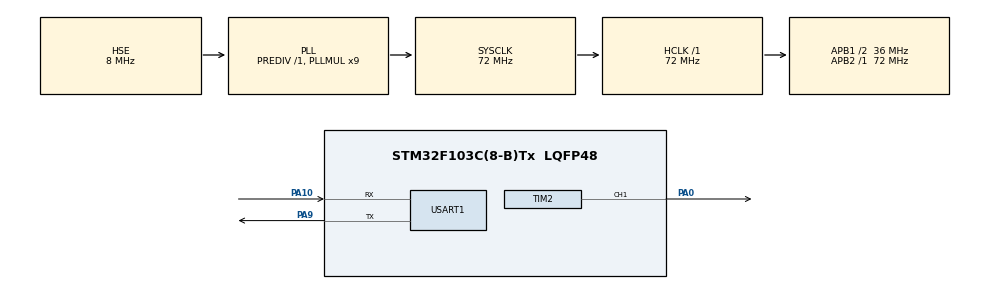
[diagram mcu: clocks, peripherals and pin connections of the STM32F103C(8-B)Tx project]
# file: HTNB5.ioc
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Mcu.Family=STM32F1
Mcu.Name=STM32F103C(8-B)Tx
Mcu.Package=LQFP48
NVIC.PriorityGroup=NVIC_PRIORITYGROUP_4
NVIC.USART1_IRQn=true\:2\:0\:true\:false\:true\:true\:true\:true
PA0-WKUP.Signal=S_TIM2_CH1_ETR
PA10.Mode=Asynchronous
PA10.Signal=USART1_RX
PA9.Mode=Asynchronous
PA9.Signal=USART1_TX
PD0-OSC_IN.Mode=HSE-External-Oscillator
PD0-OSC_IN.Signal=RCC_OSC_IN
PD1-OSC_OUT.Mode=HSE-External-Oscillator
PD1-OSC_OUT.Signal=RCC_OSC_OUT
ProjectManager.HeapSize=0x200
ProjectManager.StackSize=0x400
ProjectManager.TargetToolchain=Makefile
RCC.AHBFreq_Value=72000000
RCC.APB1CLKDivider=RCC_HCLK_DIV2
RCC.APB1Freq_Value=36000000
RCC.APB1TimFreq_Value=72000000
RCC.APB2Freq_Value=72000000
RCC.APB2TimFreq_Value=72000000
RCC.HCLKFreq_Value=72000000
RCC.PLLMUL=RCC_PLL_MUL9
RCC.PLLSourceVirtual=RCC_PLLSOURCE_HSE
RCC.SYSCLKFreq_VALUE=72000000
RCC.SYSCLKSource=RCC_SYSCLKSOURCE_PLLCLK
RCC.USBFreq_Value=72000000
SH.S_TIM2_CH1_ETR.0=TIM2_CH1,PWM Generation1 CH1
TIM2.Channel-PWM\ Generation1\ CH1=TIM_CHANNEL_1
TIM2.Period=999
TIM2.Prescaler=71
USART1.VirtualMode=VM_ASYNC
VP_SYS_VS_ND.Mode=No_Debug
board=custom

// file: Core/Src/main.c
/* USER CODE BEGIN Header */
/**
  ******************************************************************************
  * @file           : main.c
  * @brief          : Main program body
  ******************************************************************************
  * @attention
  *
  * Copyright (c) 2026 STMicroelectronics.
  * All rights reserved.
  *
  * This software is licensed under terms that can be found in the LICENSE file
  * in the root directory of this software component.
  * If no LICENSE file comes with this software, it is provided AS-IS.
  *
  ******************************************************************************
  */
/* USER CODE END Header */

#include "main.h"

/* USER CODE BEGIN Includes */
#include <string.h>
#include <stdio.h>
#include <stdlib.h>
/* USER CODE END Includes */

/* USER CODE BEGIN PD */
#define RX_BUFFER_SIZE 100
/* USER CODE END PD */

TIM_HandleTypeDef htim2;

UART_HandleTypeDef huart1;

/* USER CODE BEGIN PV */

uint8_t rx_data;

char rx_buffer[RX_BUFFER_SIZE];
uint8_t rx_index = 0;

volatile uint8_t command_ready = 0;

/* Trạng thái LED */
uint8_t led_on = 0;

/* Mức PWM gần nhất, mặc định 50% */
uint8_t pwm_percent = 50;

char tx_buffer[100];

/* USER CODE END PV */

void SystemClock_Config(void);
static void MX_GPIO_Init(void);
static void MX_TIM2_Init(void);
static void MX_USART1_UART_Init(void);

/* USER CODE BEGIN PFP */

void Set_PWM(uint8_t percent);
void Process_Command(void);
void UART_Send_String(char *str);

/* USER CODE END PFP */

/* USER CODE BEGIN 0 */

/* Hàm đặt duty PWM từ 0 -> 100% */
void Set_PWM(uint8_t percent)
{
    uint32_t compare;

    if(percent > 100)
    {
        percent = 100;
    }

    /*
     * ARR = 999
     * => tổng 1000 count
     *
     * 10%  = 100
     * 50%  = 500
     * 100% = 1000
     */
    compare = percent * 10;

    __HAL_TIM_SET_COMPARE(&htim2,
                          TIM_CHANNEL_1,
                          compare);
}

/* Gửi chuỗi qua UART */
void UART_Send_String(char *str)
{
    HAL_UART_Transmit(&huart1,
                      (uint8_t *)str,
                      strlen(str),
                      1000);
}

/* Xử lý lệnh nhận được */
void Process_Command(void)
{
    /* ---------- ON ---------- */
    if(strcmp(rx_buffer, "ON") == 0)
    {
        led_on = 1;

        /* Khôi phục mức PWM gần nhất */
        Set_PWM(pwm_percent);

        UART_Send_String("LED ON\r\n");
    }

    /* ---------- OFF ---------- */
    else if(strcmp(rx_buffer, "OFF") == 0)
    {
        led_on = 0;

        /* Tắt LED thực tế */
        Set_PWM(0);

        UART_Send_String("LED OFF\r\n");
    }

    /* ---------- PWM:xx ---------- */
    else if(strncmp(rx_buffer, "PWM:", 4) == 0)
    {
        int value;

        value = atoi(&rx_buffer[4]);

        if(value >= 0 && value <= 100)
        {
            /*
             * Luôn cập nhật giá trị PWM đã cấu hình,
             * kể cả khi LED đang OFF.
             */
            pwm_percent = (uint8_t)value;

            /*
             * Chỉ thay đổi độ sáng thực tế
             * nếu LED đang ON.
             */
            if(led_on)
            {
                Set_PWM(pwm_percent);
            }

            sprintf(tx_buffer,
                    "PWM = %d%%\r\n",
                    pwm_percent);

            UART_Send_String(tx_buffer);
        }
        else
        {
            UART_Send_String("PWM invalid\r\n");
        }
    }

    /* ---------- Status ---------- */
    else if(strcmp(rx_buffer, "Status") == 0)
    {
        if(led_on)
        {
            sprintf(tx_buffer,
                    "LED: ON, PWM: %d%%\r\n",
                    pwm_percent);
        }
        else
        {
            sprintf(tx_buffer,
                    "LED: OFF, PWM: %d%%\r\n",
                    pwm_percent);
        }

        UART_Send_String(tx_buffer);
    }

    /* ---------- Sai lệnh ---------- */
    else
    {
        UART_Send_String("Unknown command\r\n");
    }
}

/* Callback UART nhận xong 1 byte */
void HAL_UART_RxCpltCallback(UART_HandleTypeDef *huart)
{
    if(huart->Instance == USART1)
    {
        /* Nếu gặp dấu ! -> kết thúc lệnh */
        if(rx_data == '!')
        {
            rx_buffer[rx_index] = '\0';

            command_ready = 1;

            /*
             * Không nhận tiếp ngay ở đây.
             * Chờ main xử lý xong lệnh rồi nhận tiếp.
             */
        }
        else
        {
            /*
             * Chỉ lưu nếu buffer chưa đầy.
             */
            if(rx_index < RX_BUFFER_SIZE - 1)
            {
                rx_buffer[rx_index] = rx_data;
                rx_index++;
            }

            /*
             * Tiếp tục nhận byte tiếp theo.
             */
            HAL_UART_Receive_IT(&huart1,
                                &rx_data,
                                1);
        }
    }
}

/* USER CODE END 0 */

int main(void)
{

  /* MCU Configuration--------------------------------------------------------*/

  /* Reset of all peripherals, Initializes the Flash interface and the Systick. */
  HAL_Init();

  /* Configure the system clock */
  SystemClock_Config();

  /* Initialize all configured peripherals */
  MX_GPIO_Init();
  MX_TIM2_Init();
  MX_USART1_UART_Init();

  /* USER CODE BEGIN 2 */

  /*
   * Start PWM TIM2 CH1.
   */
  HAL_TIM_PWM_Start(&htim2,
                    TIM_CHANNEL_1);

  /*
   * Trạng thái ban đầu:
   * LED OFF.
   */
  Set_PWM(0);

  /*
   * Bắt đầu nhận UART byte đầu tiên bằng interrupt.
   */
  HAL_UART_Receive_IT(&huart1,
                      &rx_data,
                      1);

  UART_Send_String("System Ready\r\n");

  /* USER CODE END 2 */

  /* Infinite loop */
  while (1)
  {

    /* USER CODE BEGIN 3 */

    if(command_ready == 1)
    {
        /*
         * Xử lý lệnh vừa nhận.
         */
        Process_Command();

        /*
         * Chuẩn bị nhận lệnh mới.
         */
        rx_index = 0;

        command_ready = 0;

        /*
         * Bật lại UART interrupt để nhận lệnh tiếp theo.
         */
        HAL_UART_Receive_IT(&huart1,
                            &rx_data,
                            1);
    }

  }
  /* USER CODE END 3 */
}

void SystemClock_Config(void)
{
  RCC_OscInitTypeDef RCC_OscInitStruct = {0};
  RCC_ClkInitTypeDef RCC_ClkInitStruct = {0};

  /** Initializes the RCC Oscillators according to the specified parameters
  * in the RCC_OscInitTypeDef structure.
  */
  RCC_OscInitStruct.OscillatorType = RCC_OSCILLATORTYPE_HSE;
  RCC_OscInitStruct.HSEState = RCC_HSE_ON;
  RCC_OscInitStruct.HSEPredivValue = RCC_HSE_PREDIV_DIV1;
  RCC_OscInitStruct.HSIState = RCC_HSI_ON;

  RCC_OscInitStruct.PLL.PLLState = RCC_PLL_ON;
  RCC_OscInitStruct.PLL.PLLSource = RCC_PLLSOURCE_HSE;
  RCC_OscInitStruct.PLL.PLLMUL = RCC_PLL_MUL9;

  if (HAL_RCC_OscConfig(&RCC_OscInitStruct) != HAL_OK)
  {
    Error_Handler();
  }

  /** Initializes the CPU, AHB and APB buses clocks
  */
  RCC_ClkInitStruct.ClockType =
      RCC_CLOCKTYPE_HCLK |
      RCC_CLOCKTYPE_SYSCLK |
      RCC_CLOCKTYPE_PCLK1 |
      RCC_CLOCKTYPE_PCLK2;

  RCC_ClkInitStruct.SYSCLKSource =
      RCC_SYSCLKSOURCE_PLLCLK;

  RCC_ClkInitStruct.AHBCLKDivider =
      RCC_SYSCLK_DIV1;

  RCC_ClkInitStruct.APB1CLKDivider =
      RCC_HCLK_DIV2;

  RCC_ClkInitStruct.APB2CLKDivider =
      RCC_HCLK_DIV1;

  if (HAL_RCC_ClockConfig(&RCC_ClkInitStruct,
                          FLASH_LATENCY_2) != HAL_OK)
  {
    Error_Handler();
  }
}

static void MX_TIM2_Init(void)
{

  TIM_MasterConfigTypeDef sMasterConfig = {0};
  TIM_OC_InitTypeDef sConfigOC = {0};

  htim2.Instance = TIM2;

  /*
   * Timer clock = 72 MHz
   *
   * fPWM =
   * 72 MHz / ((71 + 1) * (999 + 1))
   *
   * = 1 kHz
   */
  htim2.Init.Prescaler = 71;

  htim2.Init.CounterMode =
      TIM_COUNTERMODE_UP;

  htim2.Init.Period = 999;

  htim2.Init.ClockDivision =
      TIM_CLOCKDIVISION_DIV1;

  htim2.Init.AutoReloadPreload =
      TIM_AUTORELOAD_PRELOAD_DISABLE;

  if (HAL_TIM_PWM_Init(&htim2) != HAL_OK)
  {
    Error_Handler();
  }

  sMasterConfig.MasterOutputTrigger =
      TIM_TRGO_RESET;

  sMasterConfig.MasterSlaveMode =
      TIM_MASTERSLAVEMODE_DISABLE;

  if (HAL_TIMEx_MasterConfigSynchronization(
          &htim2,
          &sMasterConfig) != HAL_OK)
  {
    Error_Handler();
  }

  /*
   * PWM Channel 1
   */
  sConfigOC.OCMode =
      TIM_OCMODE_PWM1;

  sConfigOC.Pulse = 0;

  sConfigOC.OCPolarity =
      TIM_OCPOLARITY_HIGH;

  sConfigOC.OCFastMode =
      TIM_OCFAST_DISABLE;

  if (HAL_TIM_PWM_ConfigChannel(
          &htim2,
          &sConfigOC,
          TIM_CHANNEL_1) != HAL_OK)
  {
    Error_Handler();
  }

  HAL_TIM_MspPostInit(&htim2);
}

static void MX_USART1_UART_Init(void)
{

  huart1.Instance = USART1;

  huart1.Init.BaudRate = 115200;

  huart1.Init.WordLength =
      UART_WORDLENGTH_8B;

  huart1.Init.StopBits =
      UART_STOPBITS_1;

  huart1.Init.Parity =
      UART_PARITY_NONE;

  huart1.Init.Mode =
      UART_MODE_TX_RX;

  huart1.Init.HwFlowCtl =
      UART_HWCONTROL_NONE;

  huart1.Init.OverSampling =
      UART_OVERSAMPLING_16;

  if (HAL_UART_Init(&huart1) != HAL_OK)
  {
    Error_Handler();
  }

}

static void MX_GPIO_Init(void)
{

  /* GPIO Ports Clock Enable */
  __HAL_RCC_GPIOD_CLK_ENABLE();
  __HAL_RCC_GPIOA_CLK_ENABLE();

}

void Error_Handler(void)
{
  __disable_irq();
  while (1)
  {
  }
}
